# PIC32MX270F256B register map
Registers are 32-bit, access not given, reset 0x0 unless marked. A register's access mark holds for its fields unless they carry their own. Offsets are from the block's base; [hi:lo] are bit positions; {n}, {i} and the like mark numbered series; 'fields as' and 'values as' point back to an identical list.

## INT — INT peripheral
Base 0xBF881000
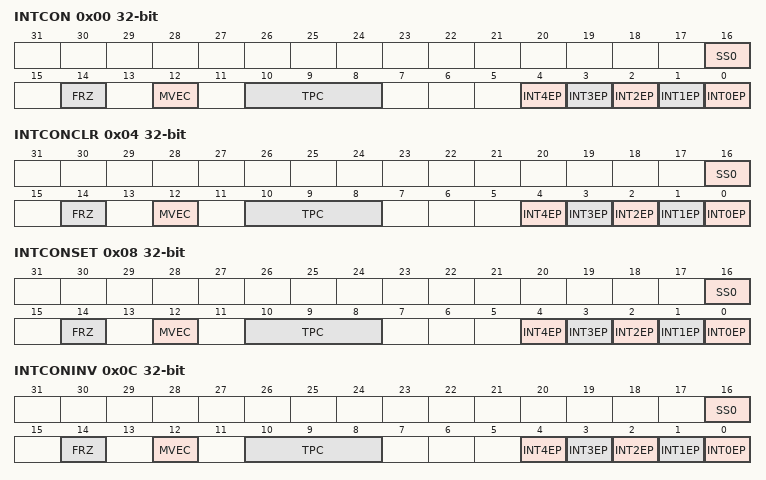
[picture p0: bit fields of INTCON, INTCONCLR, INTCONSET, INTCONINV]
0x00 INTCON
  [16] SS0, [14] FRZ, [12] MVEC, [10:8] TPC, [n] INT{n}EP (n=0..4)
0x04 INTCONCLR
  [16] SS0, [14] FRZ, [12] MVEC, [10:8] TPC, [n] INT{n}EP (n=0..4)
0x08 INTCONSET
  [16] SS0, [14] FRZ, [12] MVEC, [10:8] TPC, [n] INT{n}EP (n=0..4)
0x0C INTCONINV
  [16] SS0, [14] FRZ, [12] MVEC, [10:8] TPC, [n] INT{n}EP (n=0..4)
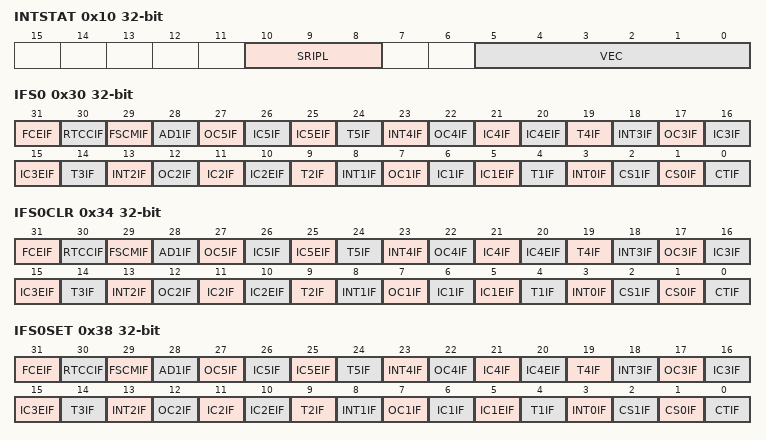
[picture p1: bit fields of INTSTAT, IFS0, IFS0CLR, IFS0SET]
0x10 INTSTAT
  [10:8] SRIPL, [5:0] VEC
0x20 IPTMR
0x24 IPTMRCLR
  [31:0] IPTMR
0x28 IPTMRSET
  [31:0] IPTMR
0x2C IPTMRINV
  [31:0] IPTMR
0x30 IFS0
  [31] FCEIF, [30] RTCCIF, [29] FSCMIF, [28] AD1IF, [5n+2] OC{n}IF (n=1..5), [5n+1] IC{n}IF (n=1..5), [5n] IC{n}EIF (n=1..5), [5n-1] T{n}IF (n=1..5), [5n+3] INT{n}IF (n=0..4), [2] CS1IF, [1] CS0IF, [0] CTIF
0x34 IFS0CLR
  fields as IFS0
0x38 IFS0SET
  fields as IFS0
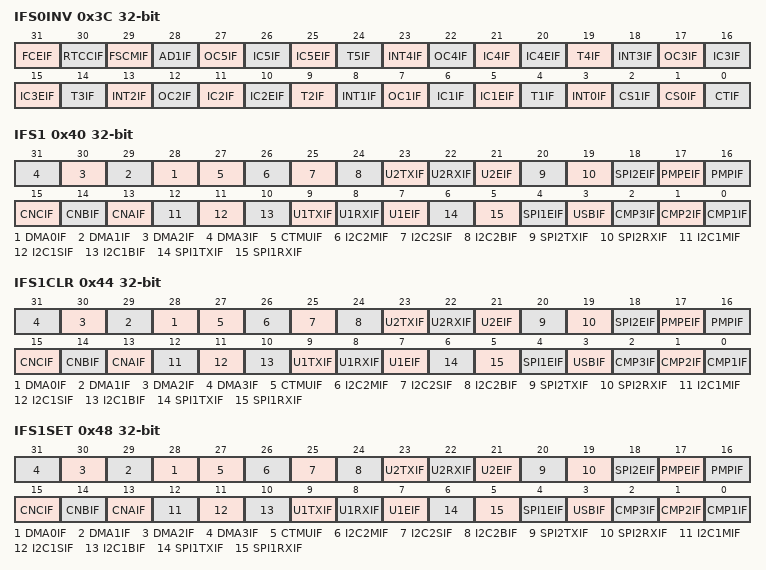
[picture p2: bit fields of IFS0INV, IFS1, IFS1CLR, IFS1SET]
0x3C IFS0INV
  fields as IFS0
0x40 IFS1
  [n+28] DMA{n}IF (n=0..3), [27] CTMUIF, [26] I2C2MIF, [25] I2C2SIF, [24] I2C2BIF, [23] U2TXIF, [22] U2RXIF, [21] U2EIF, [20] SPI2TXIF, [19] SPI2RXIF, [18] SPI2EIF, [17] PMPEIF, [16] PMPIF, [15] CNCIF, [14] CNBIF, [13] CNAIF, [12] I2C1MIF, [11] I2C1SIF, [10] I2C1BIF, [9] U1TXIF, [8] U1RXIF, [7] U1EIF, [6] SPI1TXIF, [5] SPI1RXIF, [4] SPI1EIF, [3] USBIF, [2] CMP3IF, [1] CMP2IF, [0] CMP1IF
0x44 IFS1CLR
  fields as IFS1
0x48 IFS1SET
  fields as IFS1
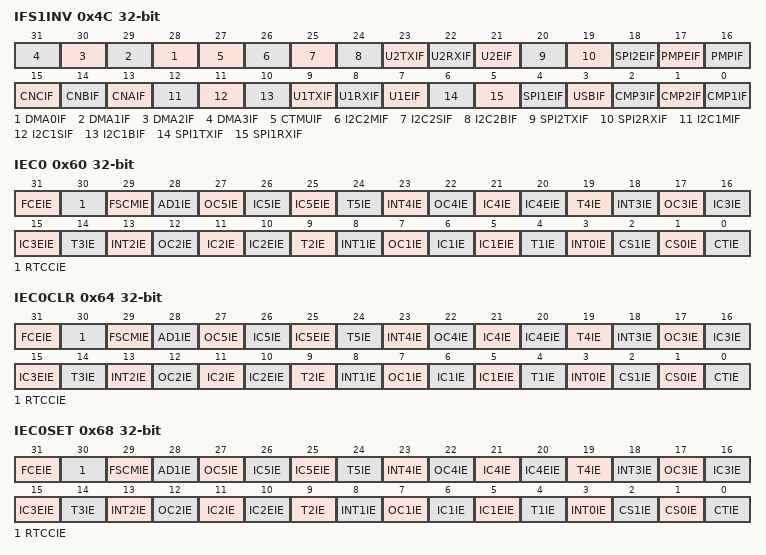
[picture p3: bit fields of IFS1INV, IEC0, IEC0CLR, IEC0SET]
0x4C IFS1INV
  fields as IFS1
0x60 IEC0
  [31] FCEIE, [30] RTCCIE, [29] FSCMIE, [28] AD1IE, [5n+2] OC{n}IE (n=1..5), [5n+1] IC{n}IE (n=1..5), [5n] IC{n}EIE (n=1..5), [5n-1] T{n}IE (n=1..5), [5n+3] INT{n}IE (n=0..4), [2] CS1IE, [1] CS0IE, [0] CTIE
0x64 IEC0CLR
  fields as IEC0
0x68 IEC0SET
  fields as IEC0
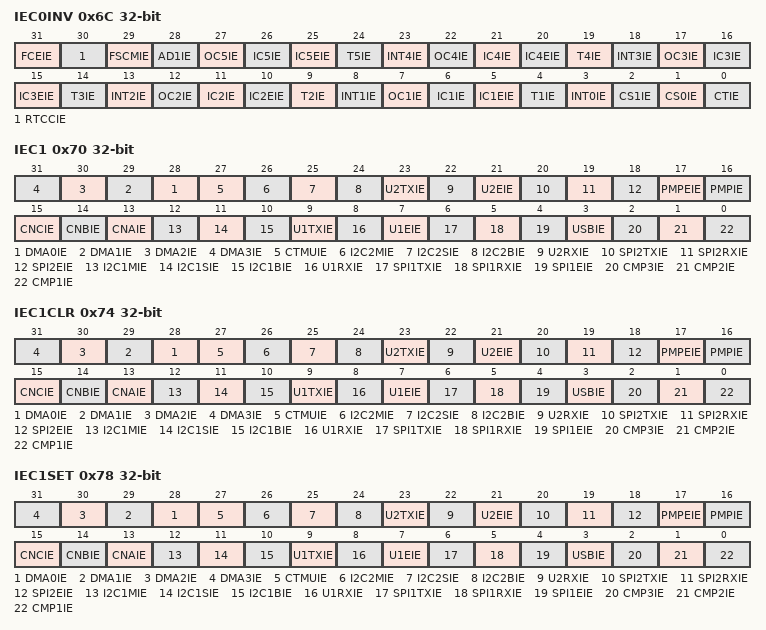
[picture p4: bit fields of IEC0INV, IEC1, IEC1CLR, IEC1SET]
0x6C IEC0INV
  fields as IEC0
0x70 IEC1
  [n+28] DMA{n}IE (n=0..3), [27] CTMUIE, [26] I2C2MIE, [25] I2C2SIE, [24] I2C2BIE, [23] U2TXIE, [22] U2RXIE, [21] U2EIE, [20] SPI2TXIE, [19] SPI2RXIE, [18] SPI2EIE, [17] PMPEIE, [16] PMPIE, [15] CNCIE, [14] CNBIE, [13] CNAIE, [12] I2C1MIE, [11] I2C1SIE, [10] I2C1BIE, [9] U1TXIE, [8] U1RXIE, [7] U1EIE, [6] SPI1TXIE, [5] SPI1RXIE, [4] SPI1EIE, [3] USBIE, [2] CMP3IE, [1] CMP2IE, [0] CMP1IE
0x74 IEC1CLR
  fields as IEC1
0x78 IEC1SET
  fields as IEC1
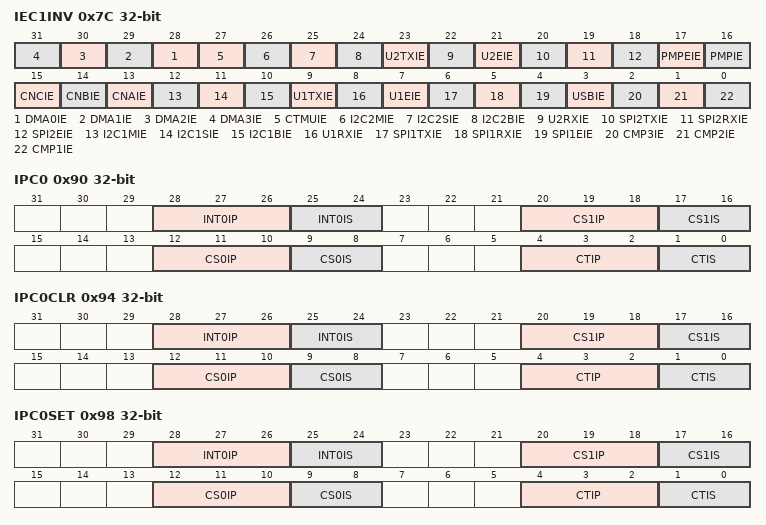
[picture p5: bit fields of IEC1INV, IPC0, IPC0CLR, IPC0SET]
0x7C IEC1INV
  fields as IEC1
0x90 IPC0
  [28:26] INT0IP, [25:24] INT0IS, [20:18] CS1IP, [17:16] CS1IS, [12:10] CS0IP, [9:8] CS0IS, [4:2] CTIP, [1:0] CTIS
0x94 IPC0CLR
  fields as IPC0
0x98 IPC0SET
  fields as IPC0
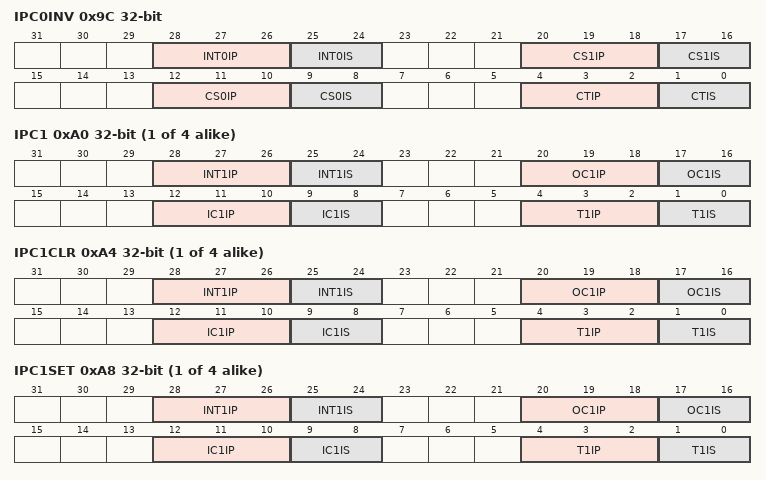
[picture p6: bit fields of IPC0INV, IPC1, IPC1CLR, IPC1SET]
0x9C IPC0INV
  fields as IPC0
{0x90+0x10*i} IPC{i} (i=1..4)
  [28:26] INT{i}IP, [25:24] INT{i}IS, [20:18] OC{i}IP, [17:16] OC{i}IS, [12:10] IC{i}IP, [9:8] IC{i}IS, [4:2] T{i}IP, [1:0] T{i}IS
{0x94+0x10*i} IPC{i}CLR (i=1..4)
  fields as IPC1
{0x98+0x10*i} IPC{i}SET (i=1..4)
  fields as IPC1
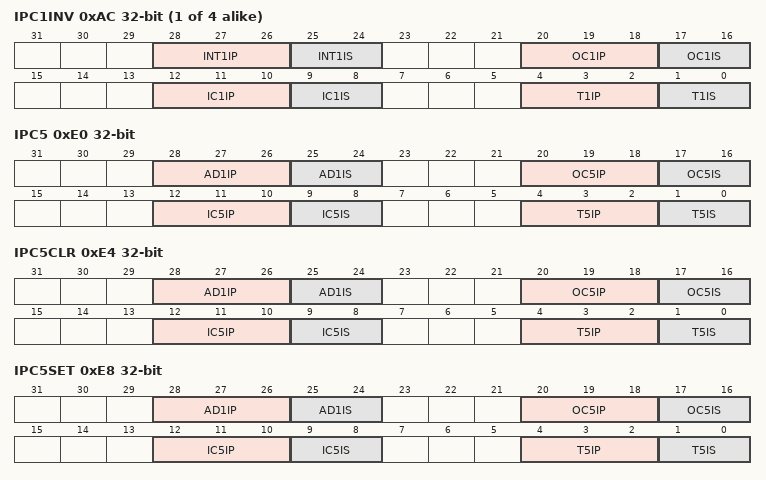
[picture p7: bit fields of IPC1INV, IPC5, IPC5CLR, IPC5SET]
{0x9C+0x10*i} IPC{i}INV (i=1..4)
  fields as IPC1
0xE0 IPC5
  [28:26] AD1IP, [25:24] AD1IS, [20:18] OC5IP, [17:16] OC5IS, [12:10] IC5IP, [9:8] IC5IS, [4:2] T5IP, [1:0] T5IS
0xE4 IPC5CLR
  fields as IPC5
0xE8 IPC5SET
  fields as IPC5
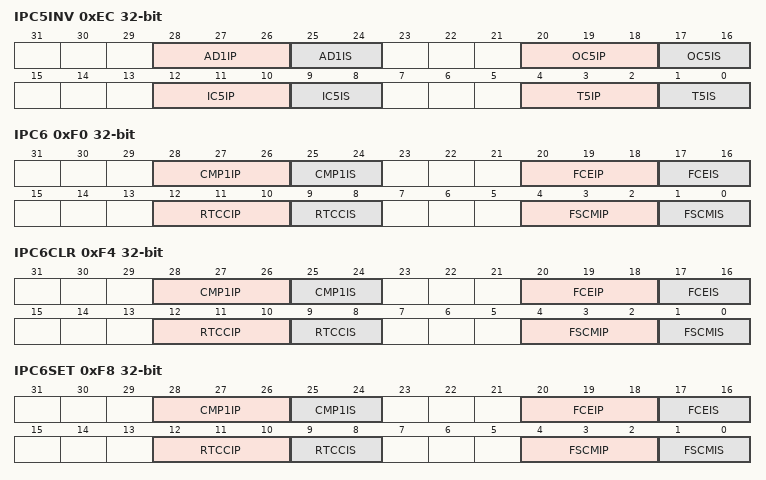
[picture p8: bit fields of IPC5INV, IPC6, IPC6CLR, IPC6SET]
0xEC IPC5INV
  fields as IPC5
0xF0 IPC6
  [28:26] CMP1IP, [25:24] CMP1IS, [20:18] FCEIP, [17:16] FCEIS, [12:10] RTCCIP, [9:8] RTCCIS, [4:2] FSCMIP, [1:0] FSCMIS
0xF4 IPC6CLR
  fields as IPC6
0xF8 IPC6SET
  fields as IPC6
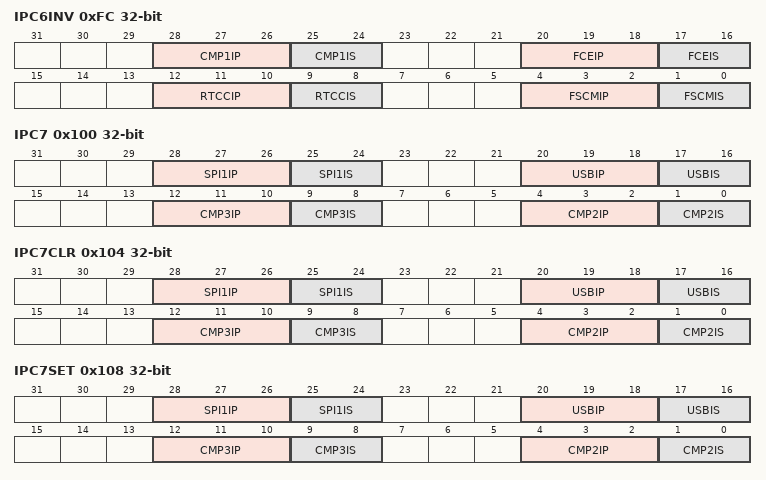
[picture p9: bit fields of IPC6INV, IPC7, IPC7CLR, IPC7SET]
0xFC IPC6INV
  fields as IPC6
0x100 IPC7
  [28:26] SPI1IP, [25:24] SPI1IS, [20:18] USBIP, [17:16] USBIS, [12:10] CMP3IP, [9:8] CMP3IS, [4:2] CMP2IP, [1:0] CMP2IS
0x104 IPC7CLR
  fields as IPC7
0x108 IPC7SET
  fields as IPC7
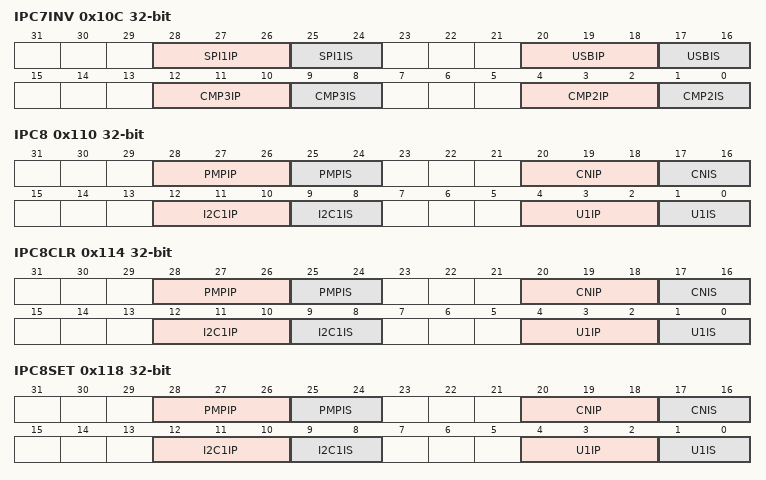
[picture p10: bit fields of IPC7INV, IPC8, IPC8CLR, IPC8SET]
0x10C IPC7INV
  fields as IPC7
0x110 IPC8
  [28:26] PMPIP, [25:24] PMPIS, [20:18] CNIP, [17:16] CNIS, [12:10] I2C1IP, [9:8] I2C1IS, [4:2] U1IP, [1:0] U1IS
0x114 IPC8CLR
  fields as IPC8
0x118 IPC8SET
  fields as IPC8
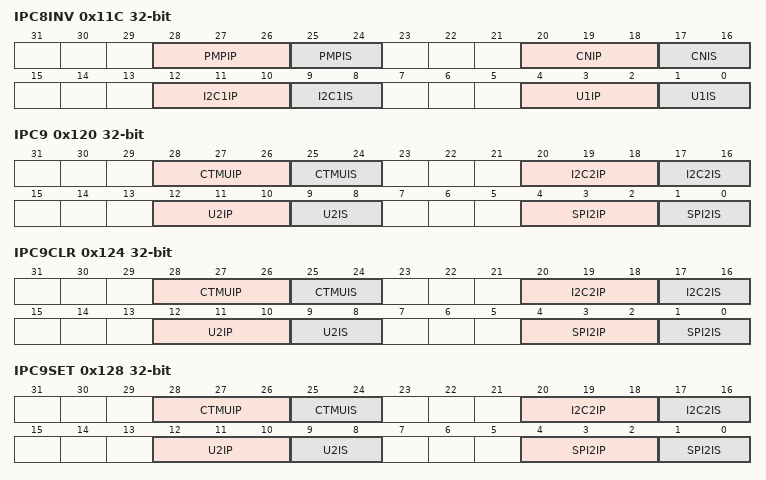
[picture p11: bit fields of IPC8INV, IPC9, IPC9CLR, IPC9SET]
0x11C IPC8INV
  fields as IPC8
0x120 IPC9
  [28:26] CTMUIP, [25:24] CTMUIS, [20:18] I2C2IP, [17:16] I2C2IS, [12:10] U2IP, [9:8] U2IS, [4:2] SPI2IP, [1:0] SPI2IS
0x124 IPC9CLR
  fields as IPC9
0x128 IPC9SET
  fields as IPC9
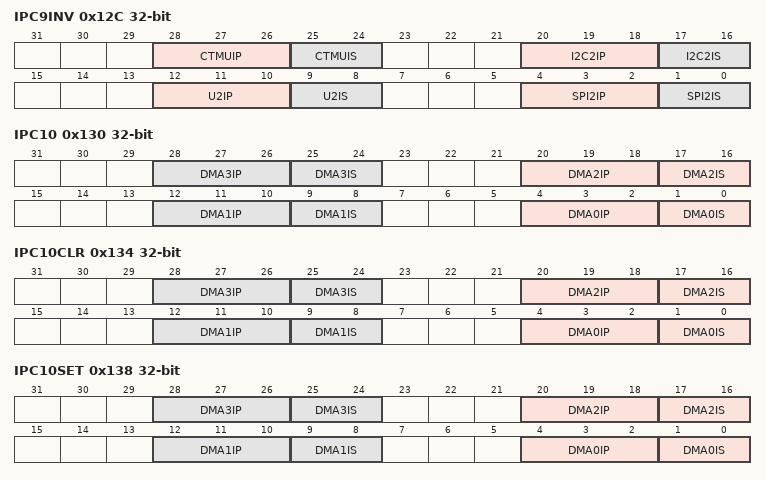
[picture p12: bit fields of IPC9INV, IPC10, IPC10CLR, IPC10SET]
0x12C IPC9INV
  fields as IPC9
0x130 IPC10
  [8n+4:8n+2] DMA{n}IP (n=0..3), [8n+1:8n] DMA{n}IS (n=0..3)
0x134 IPC10CLR
  [8n+4:8n+2] DMA{n}IP (n=0..3), [8n+1:8n] DMA{n}IS (n=0..3)
0x138 IPC10SET
  [8n+4:8n+2] DMA{n}IP (n=0..3), [8n+1:8n] DMA{n}IS (n=0..3)
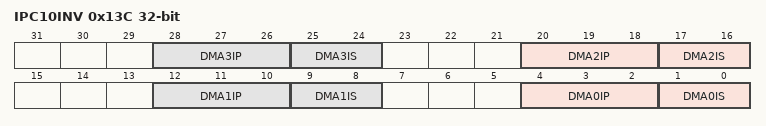
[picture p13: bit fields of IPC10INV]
0x13C IPC10INV
  [8n+4:8n+2] DMA{n}IP (n=0..3), [8n+1:8n] DMA{n}IS (n=0..3)
